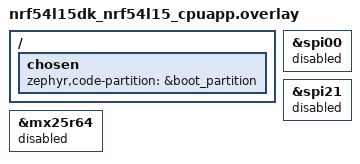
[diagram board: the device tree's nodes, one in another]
/*
 * Copyright (c) 2024 Nordic Semiconductor ASA
 *
 * SPDX-License-Identifier: LicenseRef-Nordic-5-Clause
 */

#include "../../../boards/nrf54l15dk_nrf54l15_cpuapp.overlay"

/ {
	chosen {
		zephyr,code-partition = &boot_partition;
	};
};

&spi00 {
	status = "disabled";
};

&spi21 {
	status = "disabled";
};

/* Secondary slot is in internal RRAM - disable external flash for MCUboot */
&mx25r64 {
	status = "disabled";
};
